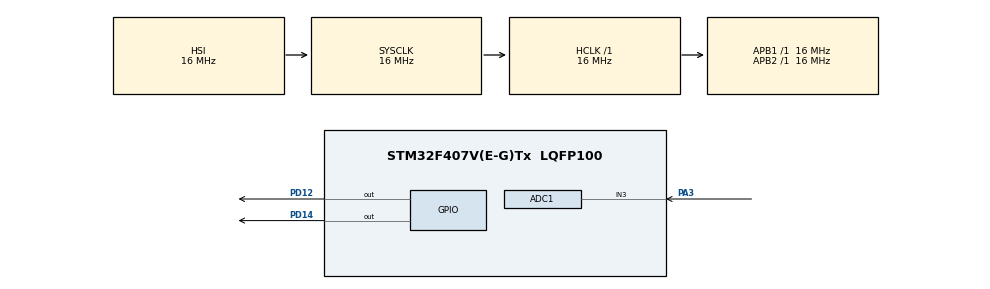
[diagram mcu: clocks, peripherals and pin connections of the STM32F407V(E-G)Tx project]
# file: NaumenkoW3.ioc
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ADC1.Channel-0\#ChannelRegularConversion=ADC_CHANNEL_3
ADC1.NbrOfConversionFlag=1
ADC1.Rank-0\#ChannelRegularConversion=1
ADC1.SamplingTime-0\#ChannelRegularConversion=ADC_SAMPLETIME_480CYCLES
ADC1.master=1
Mcu.Family=STM32F4
Mcu.Name=STM32F407V(E-G)Tx
Mcu.Package=LQFP100
NVIC.ADC_IRQn=true\:0\:0\:false\:false\:true\:true\:true\:true
NVIC.PriorityGroup=NVIC_PRIORITYGROUP_4
PA3.Signal=ADCx_IN3
PD12.Signal=GPIO_Output
PD14.Signal=GPIO_Output
ProjectManager.HeapSize=0x200
ProjectManager.StackSize=0x400
ProjectManager.TargetToolchain=STM32CubeIDE
RCC.AHBFreq_Value=16000000
RCC.APB1Freq_Value=16000000
RCC.APB2Freq_Value=16000000
RCC.CortexFreq_Value=16000000
RCC.HSE_VALUE=25000000
RCC.HSI_VALUE=16000000
RCC.LSE_VALUE=32768
RCC.SYSCLKFreq_VALUE=16000000
RCC.VCOOutputFreq_Value=192000000
SH.ADCx_IN3.0=ADC1_IN3,IN3
board=custom

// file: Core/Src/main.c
/* USER CODE BEGIN Header */
/**
  ******************************************************************************
  * @file           : main.c
  * @brief          : Main program body
  ******************************************************************************
  * @attention
  *
  * Copyright (c) 2026 STMicroelectronics.
  * All rights reserved.
  *
  * This software is licensed under terms that can be found in the LICENSE file
  * in the root directory of this software component.
  * If no LICENSE file comes with this software, it is provided AS-IS.
  *
  ******************************************************************************
  */
/* USER CODE END Header */
#include "main.h"

ADC_HandleTypeDef hadc1;

/* USER CODE BEGIN PV */

/* Global variables */
uint32_t adc_sum = 0;
uint16_t adc_counter = 0;
float voltage = 0;
uint32_t adc_avg = 0;

/* USER CODE END PV */

void SystemClock_Config(void);
static void MX_GPIO_Init(void);
static void MX_ADC1_Init(void);

/* USER CODE BEGIN 0 */

void HAL_ADC_ConvCpltCallback(ADC_HandleTypeDef* hadc)
{
    // Make sure the interrupt came from ADC1
    if(hadc->Instance == ADC1)
    {
        adc_sum += HAL_ADC_GetValue(hadc);
        adc_counter++;

        // Accumulate 256 samples for averaging
        if(adc_counter >= 256)
        {
            // Average value (divide by 256 via right shift)
            adc_avg = adc_sum >> 8;

            // Convert ADC code to voltage (Vref = 3.3V, 12-bit resolution)
            voltage = (adc_avg * 3.3f) / 4095.0f;

            if (adc_avg < 2048) {
                HAL_GPIO_WritePin(GPIOD, GPIO_PIN_14, GPIO_PIN_SET);
                HAL_GPIO_WritePin(GPIOD, GPIO_PIN_12, GPIO_PIN_RESET);
            } else {
                HAL_GPIO_WritePin(GPIOD, GPIO_PIN_14, GPIO_PIN_RESET);
                HAL_GPIO_WritePin(GPIOD, GPIO_PIN_12, GPIO_PIN_SET);
            }

            // Reset sum and counter before the next cycle
            adc_sum = 0;
            adc_counter = 0;
        }

        // Trigger the next conversion
        HAL_ADC_Start_IT(hadc);
    }
}

/* USER CODE END 0 */

int main(void)
{

  /* MCU Configuration--------------------------------------------------------*/

  /* Reset of all peripherals, Initializes the Flash interface and the Systick. */
  HAL_Init();

  /* Configure the system clock */
  SystemClock_Config();

  /* Initialize all configured peripherals */
  MX_GPIO_Init();
  MX_ADC1_Init();

  /* Infinite loop */
  /* USER CODE BEGIN WHILE */

  HAL_ADC_Start_IT(&hadc1);

  while (1)
  {
    /* USER CODE END WHILE */

  }
}

void SystemClock_Config(void)
{
  RCC_OscInitTypeDef RCC_OscInitStruct = {0};
  RCC_ClkInitTypeDef RCC_ClkInitStruct = {0};

  /** Configure the main internal regulator output voltage
  */
  __HAL_RCC_PWR_CLK_ENABLE();
  __HAL_PWR_VOLTAGESCALING_CONFIG(PWR_REGULATOR_VOLTAGE_SCALE1);

  /** Initializes the RCC Oscillators according to the specified parameters
  * in the RCC_OscInitTypeDef structure.
  */
  RCC_OscInitStruct.OscillatorType = RCC_OSCILLATORTYPE_HSI;
  RCC_OscInitStruct.HSIState = RCC_HSI_ON;
  RCC_OscInitStruct.HSICalibrationValue = RCC_HSICALIBRATION_DEFAULT;
  RCC_OscInitStruct.PLL.PLLState = RCC_PLL_NONE;
  if (HAL_RCC_OscConfig(&RCC_OscInitStruct) != HAL_OK)
  {
    Error_Handler();
  }

  /** Initializes the CPU, AHB and APB buses clocks
  */
  RCC_ClkInitStruct.ClockType = RCC_CLOCKTYPE_HCLK|RCC_CLOCKTYPE_SYSCLK
                              |RCC_CLOCKTYPE_PCLK1|RCC_CLOCKTYPE_PCLK2;
  RCC_ClkInitStruct.SYSCLKSource = RCC_SYSCLKSOURCE_HSI;
  RCC_ClkInitStruct.AHBCLKDivider = RCC_SYSCLK_DIV1;
  RCC_ClkInitStruct.APB1CLKDivider = RCC_HCLK_DIV1;
  RCC_ClkInitStruct.APB2CLKDivider = RCC_HCLK_DIV1;

  if (HAL_RCC_ClockConfig(&RCC_ClkInitStruct, FLASH_LATENCY_0) != HAL_OK)
  {
    Error_Handler();
  }
}

static void MX_ADC1_Init(void)
{

  ADC_ChannelConfTypeDef sConfig = {0};

  /** Configure the global features of the ADC (Clock, Resolution, Data Alignment and number of conversion)
  */
  hadc1.Instance = ADC1;
  hadc1.Init.ClockPrescaler = ADC_CLOCK_SYNC_PCLK_DIV2;
  hadc1.Init.Resolution = ADC_RESOLUTION_12B;
  hadc1.Init.ScanConvMode = DISABLE;
  hadc1.Init.ContinuousConvMode = DISABLE;
  hadc1.Init.DiscontinuousConvMode = DISABLE;
  hadc1.Init.ExternalTrigConvEdge = ADC_EXTERNALTRIGCONVEDGE_NONE;
  hadc1.Init.ExternalTrigConv = ADC_SOFTWARE_START;
  hadc1.Init.DataAlign = ADC_DATAALIGN_RIGHT;
  hadc1.Init.NbrOfConversion = 1;
  hadc1.Init.DMAContinuousRequests = DISABLE;
  hadc1.Init.EOCSelection = ADC_EOC_SINGLE_CONV;
  if (HAL_ADC_Init(&hadc1) != HAL_OK)
  {
    Error_Handler();
  }

  /** Configure for the selected ADC regular channel its corresponding rank in the sequencer and its sample time.
  */
  sConfig.Channel = ADC_CHANNEL_3;
  sConfig.Rank = 1;
  sConfig.SamplingTime = ADC_SAMPLETIME_480CYCLES;
  if (HAL_ADC_ConfigChannel(&hadc1, &sConfig) != HAL_OK)
  {
    Error_Handler();
  }

}

static void MX_GPIO_Init(void)
{
  GPIO_InitTypeDef GPIO_InitStruct = {0};

  /* GPIO Ports Clock Enable */
  __HAL_RCC_GPIOA_CLK_ENABLE();
  __HAL_RCC_GPIOD_CLK_ENABLE();

  /*Configure GPIO pin Output Level */
  HAL_GPIO_WritePin(GPIOD, GPIO_PIN_12|GPIO_PIN_14, GPIO_PIN_RESET);

  /*Configure GPIO pins : PD12 PD14 */
  GPIO_InitStruct.Pin = GPIO_PIN_12|GPIO_PIN_14;
  GPIO_InitStruct.Mode = GPIO_MODE_OUTPUT_PP;
  GPIO_InitStruct.Pull = GPIO_NOPULL;
  GPIO_InitStruct.Speed = GPIO_SPEED_FREQ_LOW;
  HAL_GPIO_Init(GPIOD, &GPIO_InitStruct);

}

void Error_Handler(void)
{
  __disable_irq();
  while (1)
  {
  }
}
